CM_ "Provisional navigation / cluster-turn probe definitions for ACURA_MDX_3G.";
CM_ "Evidence route: 3792d010590cb83a|00000235--2c1d904186 (full rlogs, ~927 s).";
CM_ "IDs 546/559/460/808/1348 are car-side probe messages (buses 0 and 130).";
CM_ "Camera-path raw bytes: CRUISE 804 NAV_MAP_BYTE*, ACC_HUD 780 NAV_30C_BYTE* (_honda_common); BRAKE_COMMAND 506 NAV_1FA_BYTE* (_nidec_common); LKAS_HUD 829 NAV_33D_* (_lkas_hud_5byte; first 5 bytes of 8-byte bus-128 frames).";
CM_ "NAV_*_PHASE scale: 15 m per raw unit (4-state countdown, ±0 m at maneuver; provisional).";

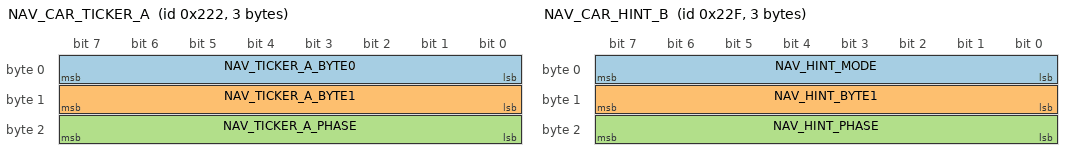
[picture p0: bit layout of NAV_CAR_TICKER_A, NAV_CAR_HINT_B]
BO_ 546 NAV_CAR_TICKER_A: 3 XXX
 SG_ NAV_TICKER_A_BYTE0 : 7|8@0+ (1,0) [0|255] "" XXX
 SG_ NAV_TICKER_A_BYTE1 : 15|8@0+ (1,0) [0|255] "" XXX
 SG_ NAV_TICKER_A_PHASE : 23|8@0+ (15,0) [0|3825] "m" XXX

BO_ 559 NAV_CAR_HINT_B: 3 XXX
 SG_ NAV_HINT_MODE : 7|8@0+ (1,0) [0|255] "" XXX
 SG_ NAV_HINT_BYTE1 : 15|8@0+ (1,0) [0|255] "" XXX
 SG_ NAV_HINT_PHASE : 23|8@0+ (15,0) [0|3825] "m" XXX

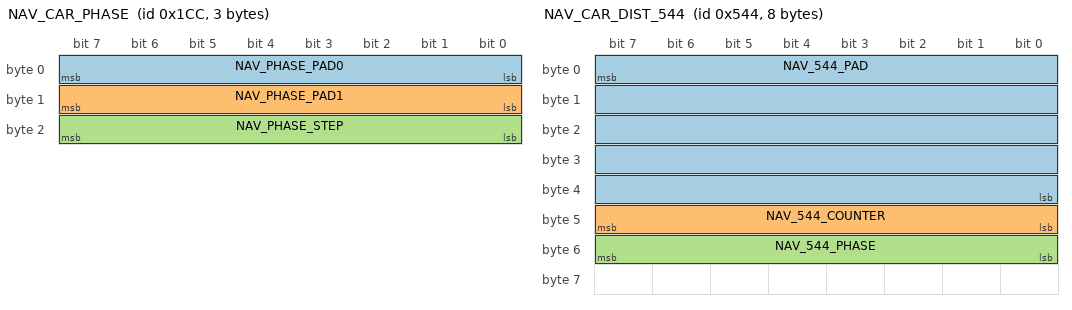
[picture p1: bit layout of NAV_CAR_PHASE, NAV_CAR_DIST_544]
BO_ 460 NAV_CAR_PHASE: 3 XXX
 SG_ NAV_PHASE_PAD0 : 7|8@0+ (1,0) [0|255] "" XXX
 SG_ NAV_PHASE_PAD1 : 15|8@0+ (1,0) [0|255] "" XXX
 SG_ NAV_PHASE_STEP : 23|8@0+ (15,0) [0|3825] "m" XXX

BO_ 808 NAV_CAR_COUNTDOWN: 8 XXX
 SG_ NAV_COUNTDOWN_PAD : 7|56@0+ (1,0) [0|1.0141204802792e+15] "" XXX
 SG_ NAV_COUNTDOWN_PHASE : 63|8@0+ (15,0) [0|3825] "m" XXX

BO_ 1348 NAV_CAR_DIST_544: 8 XXX
 SG_ NAV_544_PAD : 7|40@0+ (1,0) [0|1.099511627776e+12] "" XXX
 SG_ NAV_544_COUNTER : 47|8@0+ (1,0) [0|255] "" XXX
 SG_ NAV_544_PHASE : 55|8@0+ (15,0) [0|3825] "m" XXX

VAL_ 546 NAV_TICKER_A_BYTE0 162 "active_prefix_a2" ;
VAL_ 546 NAV_TICKER_A_BYTE1 128 "active_prefix_80" ;
VAL_ 559 NAV_HINT_MODE 145 "default_or_right_aisle" 125 "turn_hint_left" ;
VAL_ 559 NAV_HINT_BYTE1 64 "fixed_second_byte" ;
